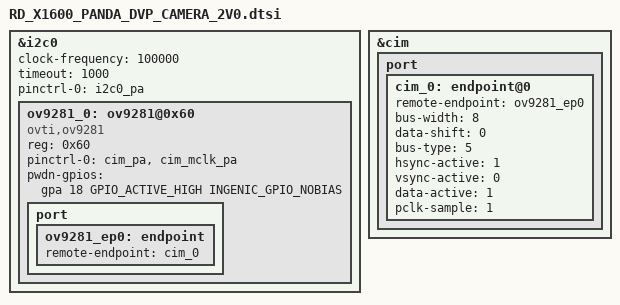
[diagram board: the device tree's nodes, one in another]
&i2c0 {
	status = "okay";
	clock-frequency = <100000>;
	timeout = <1000>;
	pinctrl-names = "default";
	pinctrl-0 = <&i2c0_pa>;

	ov9281_0:ov9281@0x60 {
		status = "okay";
		compatible = "ovti,ov9281";
		reg = <0x60>;
		pinctrl-names = "default";
		pinctrl-0 = <&cim_pa>, <&cim_mclk_pa>;

		pwdn-gpios = <&gpa 18 GPIO_ACTIVE_HIGH INGENIC_GPIO_NOBIAS>;

		port {
			ov9281_ep0:endpoint {
				remote-endpoint = <&cim_0>;
			};
		};
	};
};

&cim {
	status = "okay";
	port {
		cim_0: endpoint@0 {
			remote-endpoint = <&ov9281_ep0>;
			bus-width = <8>;
			data-shift = <0>;
			bus-type = <5>;
			hsync-active = <1>;
			vsync-active = <0>;
			data-active = <1>;
			pclk-sample = <1>;
		};
	};
};

